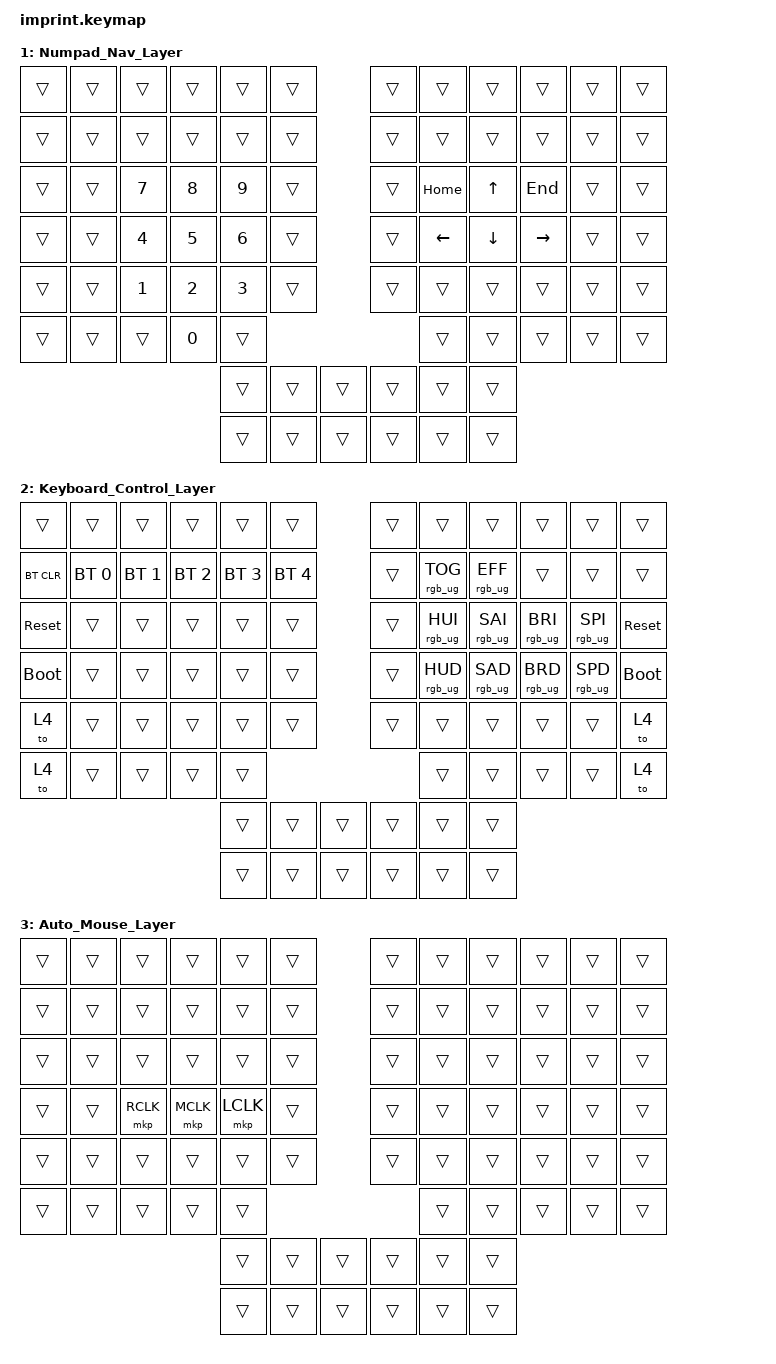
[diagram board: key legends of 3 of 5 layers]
#include <input/processors.dtsi>
#include <dt-bindings/zmk/input_transform.h>
#include <behaviors.dtsi>
#include <dt-bindings/zmk/bt.h>
#include <dt-bindings/zmk/keys.h>
#include <dt-bindings/zmk/pointing.h>
#include <dt-bindings/zmk/rgb.h>

/ {
    chosen { zmk,matrix-transform = &imprint_function_row_full_bottom_row; };

    keymap {
        compatible = "zmk,keymap";

        default_layer {
            bindings = <
&none ESC    &none F1  &none F2    &none F3    &none F4    &none F5              &none F6     &none F7    &none F8     &none F9    &none F10   &none F11
&kp EQUAL  &kp N1  &kp N2    &kp N3    &kp N4    &kp N5              &kp N6     &kp N7    &kp N8     &kp N9    &kp N0    &kp MINUS
&kp TAB    &kp Q   &kp W     &kp E     &kp R     &kp T               &kp Y      &kp U     &kp I      &kp O     &kp P     &kp BSLH
&kp LCTRL  &kp A   &kp S     &kp D     &kp F     &kp G               &kp H      &kp J     &kp K      &kp L     &kp SEMI  &kp SQT
&kp LSHFT  &kp Z   &kp X     &kp C     &kp V     &kp B               &kp N      &kp M     &kp COMMA  &kp DOT   &kp FSLH  &kp RSHFT
&trans     &trans  &kp LGUI  &kp LALT  &trans                                   &trans    &kp LBKT   &kp RBKT  &trans    &trans
                                       &kp RET   &kp DEL  &kp ESC    &kp GRAVE  &kp BSPC  &kp SPACE
                                       &kp LGUI  &mo 1    &mo 2      &kp CAPS   &mo 2     &mo 1
            >;
        };

        Numpad_Nav_Layer {
            bindings = <
&trans  &trans  &trans  &trans  &trans  &trans            &trans  &trans    &trans    &trans     &trans  &trans
&trans  &trans  &trans  &trans  &trans  &trans            &trans  &trans    &trans    &trans     &trans  &trans
&trans  &trans  &kp N7  &kp N8  &kp N9  &trans            &trans  &kp HOME  &kp UP    &kp END    &trans  &trans
&trans  &trans  &kp N4  &kp N5  &kp N6  &trans            &trans  &kp LEFT  &kp DOWN  &kp RIGHT  &trans  &trans
&trans  &trans  &kp N1  &kp N2  &kp N3  &trans            &trans  &trans    &trans    &trans     &trans  &trans
&trans  &trans  &trans  &kp N0  &trans                            &trans    &trans    &trans     &trans  &trans
                                &trans  &trans  &trans    &trans  &trans    &trans
                                &trans  &trans  &trans    &trans  &trans    &trans
            >;
        };

        Keyboard_Control_Layer {
            bindings = <
&trans       &trans        &trans        &trans        &trans        &trans                  &trans  &trans           &trans           &trans           &trans           &trans
&bt BT_CLR   &bt BT_SEL 0  &bt BT_SEL 1  &bt BT_SEL 2  &bt BT_SEL 3  &bt BT_SEL 4            &trans  &rgb_ug RGB_TOG  &rgb_ug RGB_EFF  &trans           &trans           &trans
&sys_reset   &trans        &trans        &trans        &trans        &trans                  &trans  &rgb_ug RGB_HUI  &rgb_ug RGB_SAI  &rgb_ug RGB_BRI  &rgb_ug RGB_SPI  &sys_reset
&bootloader  &trans        &trans        &trans        &trans        &trans                  &trans  &rgb_ug RGB_HUD  &rgb_ug RGB_SAD  &rgb_ug RGB_BRD  &rgb_ug RGB_SPD  &bootloader
&to 4        &trans        &trans        &trans        &trans        &trans                  &trans  &trans           &trans           &trans           &trans           &to 4
&to 4        &trans        &trans        &trans        &trans                                        &trans           &trans           &trans           &trans           &to 4
                                                       &trans        &trans        &trans    &trans  &trans           &trans
                                                       &trans        &trans        &trans    &trans  &trans           &trans
            >;
        };

        Auto_Mouse_Layer {
            bindings = <
&trans  &trans  &trans     &trans     &trans     &trans            &trans  &trans  &trans  &trans  &trans  &trans
&trans  &trans  &trans     &trans     &trans     &trans            &trans  &trans  &trans  &trans  &trans  &trans
&trans  &trans  &trans     &trans     &trans     &trans            &trans  &trans  &trans  &trans  &trans  &trans
&trans  &trans  &mkp RCLK  &mkp MCLK  &mkp LCLK  &trans            &trans  &trans  &trans  &trans  &trans  &trans
&trans  &trans  &trans     &trans     &trans     &trans            &trans  &trans  &trans  &trans  &trans  &trans
&trans  &trans  &trans     &trans     &trans                               &trans  &trans  &trans  &trans  &trans
                                      &trans     &trans  &trans    &trans  &trans  &trans
                                      &trans     &trans  &trans    &trans  &trans  &trans
            >;
        };

        factory_test {
            bindings = <
&none N0  &none N1  &none N2  &none N3  &none N4  &none N5            &none N6  &none N7  &none N8  &none N9  &none N0  &none N1
&kp N2  &kp N3  &kp N4  &kp N5  &kp N6  &kp N7            &kp N8  &kp N9  &kp N0  &kp N1  &kp N2  &kp N3
&kp N4  &kp N5  &kp N6  &kp N7  &kp N8  &kp N9            &kp N0  &kp N1  &kp N2  &kp N3  &kp N4  &kp N5
&kp N6  &kp N7  &kp N8  &kp N9  &kp N0  &kp N1            &kp N2  &kp N3  &kp N4  &kp N5  &kp N6  &kp N7
&kp N8  &kp N9  &kp N0  &kp N1  &kp N2  &kp N3            &kp N4  &kp N5  &kp N6  &kp N7  &kp N8  &kp N9
&kp N0  &kp N1  &kp N2  &kp N3  &kp N4                            &kp N6  &kp N7  &kp N8  &kp N9  &kp N0
                                &kp N1  &kp N2  &kp N3    &kp N4  &kp N5  &kp N6
                                &kp N7  &kp N8  &kp N9    &kp N0  &kp N1  &kp N2
            >;
        };
    };
};

//right hand trackball configuration

&trackball_peripheral_listener {
    input-processors =
        // this gets it to the default installation orientation,
        <&zip_xy_transform INPUT_TRANSFORM_XY_SWAP>;

    // activate layer 3 within 500ms of the trackball moving
    // <&zip_temp_layer 3 500>;
};

//left hand trackball configuration

&trackball_central_listener {
    input-processors =
        // this gets it to the default installation orientation,
        <&zip_xy_transform INPUT_TRANSFORM_XY_SWAP>,
        // multiply sensitivity by 1, divide by 3 (make it slower for scrolling),
        <&zip_xy_scaler 1 3>,
        // make this trackball output scrolling events by default instead of cursor movement,
        <&zip_xy_to_scroll_mapper>,
        // invert vertical scrolling so that the view moves in the same direction as the top of the trackball.,
        <&zip_scroll_transform INPUT_TRANSFORM_Y_INVERT>;
};
